# STM32F469 register map
File version: 1.9
CPU: CM4 r0p1, little endian, MPU, FPU, 4 interrupt priority bits
Registers are 32-bit, read-write, reset 0x0 unless marked. A register's access mark holds for its fields unless they carry their own. Offsets are from the block's base; [hi:lo] are bit positions; {n}, {i} and the like mark numbered series; <NAME> marks a mode.

## DSI — DSI Host
Base 0x40016C00
0x00 VR ro reset 0x3133302A — DSI Host version register
  [31:0] VERSION — Version of the DSI Host This read-only register contains the version of the DSI Host
0x04 CR — DSI Host control register
  [0] EN — Enable This bit configures the DSI Host in either power-up mode or to reset.
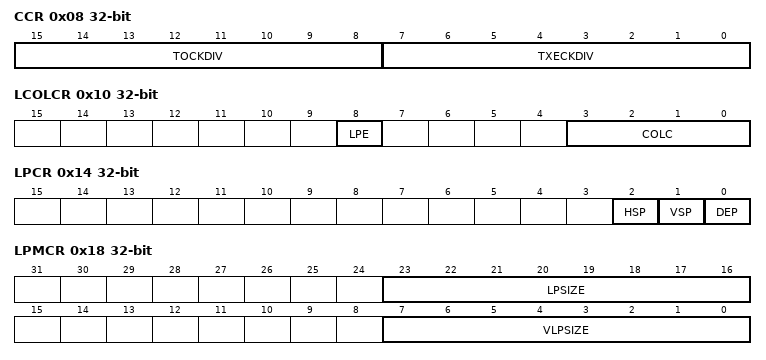
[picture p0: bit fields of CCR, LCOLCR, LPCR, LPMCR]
0x08 CCR — DSI Host clock control register
  [15:8] TOCKDIV — Timeout clock division This field indicates the division factor for the timeout clock used as the timing unit in the configuration of HS to LP and LP to HS transition error.
  [7:0] TXECKDIV — TX escape clock division This field indicates the division factor for the TX escape clock source (lanebyteclk). The values 0 and 1 stop the TX_ESC clock generation.
0x0C LVCIDR — DSI Host LTDC VCID register
  [1:0] VCID — Virtual channel ID These bits configure the virtual channel ID for the LTDC interface traffic.
0x10 LCOLCR — DSI Host LTDC color coding register
  [8] LPE — Loosely packet enable This bit enables the loosely packed variant to 18-bit configuration
  [3:0] COLC — Color coding This field configures the DPI color coding. Others: Reserved
0x14 LPCR — DSI Host LTDC polarity configuration register
  [2] HSP — HSYNC polarity This bit configures the polarity of HSYNC pin.
  [1] VSP — VSYNC polarity This bit configures the polarity of VSYNC pin.
  [0] DEP — Data enable polarity This bit configures the polarity of data enable pin.
0x18 LPMCR — DSI Host low-power mode configuration register
  [23:16] LPSIZE — Largest packet size This field is used for the transmission of commands in low-power mode. It defines the size, in bytes, of the largest packet that can fit in a line during VSA, VBP and VFP regions.
  [7:0] VLPSIZE — VACT largest packet size This field is used for the transmission of commands in low-power mode. It defines the size, in bytes, of the largest packet that can fit in a line during VACT regions.
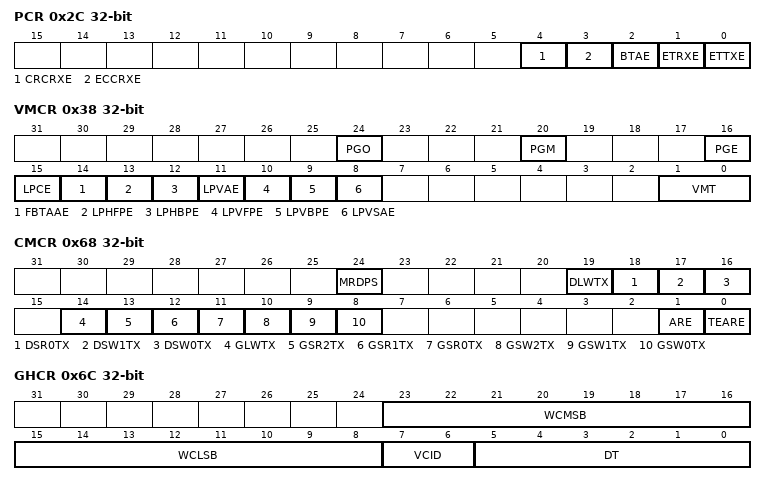
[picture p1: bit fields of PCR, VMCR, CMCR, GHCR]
0x2C PCR — DSI Host protocol configuration register
  [4] CRCRXE — CRC reception enable This bit enables the CRC reception and error reporting.
  [3] ECCRXE — ECC reception enable This bit enables the ECC reception, error correction and reporting.
  [2] BTAE — Bus-turn-around enable This bit enables the bus-turn-around (BTA) request.
  [1] ETRXE — EoTp reception enable This bit enables the EoTp reception.
  [0] ETTXE — EoTp transmission enable This bit enables the EoTP transmission.
0x30 GVCIDR — DSI Host generic VCID register
  [1:0] VCID — Virtual channel ID This field indicates the generic interface read-back virtual channel identification.
0x34 MCR reset 0x1 — DSI Host mode configuration register
  [0] CMDM — Command mode This bit configures the DSI Host in either video or command mode.
0x38 VMCR — DSI Host video mode configuration register
  [24] PGO — Pattern generator orientation This bit configures the color bar orientation.
  [20] PGM — Pattern generator mode This bit configures the pattern generator mode.
  [16] PGE — Pattern generator enable This bit enables the video mode pattern generator.
  [15] LPCE — Low-power command enable This bit enables the command transmission only in low-power mode.
  [14] FBTAAE — Frame bus-turn-around acknowledge enable This bit enables the request for an acknowledge response at the end of a frame.
  [13] LPHFPE — Low-power horizontal front-porch enable This bit enables the return to low-power inside the horizontal front-porch (HFP) period when timing allows.
  [12] LPHBPE — Low-power horizontal back-porch enable This bit enables the return to low-power inside the horizontal back-porch (HBP) period when timing allows.
  [11] LPVAE — Low-power vertical active enable This bit enables to return to low-power inside the vertical active (VACT) period when timing allows.
  [10] LPVFPE — Low-power vertical front-porch enable This bit enables to return to low-power inside the vertical front-porch (VFP) period when timing allows.
  [9] LPVBPE — Low-power vertical back-porch enable This bit enables to return to low-power inside the vertical back-porch (VBP) period when timing allows.
  [8] LPVSAE — Low-power vertical sync active enable This bit enables to return to low-power inside the vertical sync time (VSA) period when timing allows.
  [1:0] VMT — Video mode type This field configures the video mode transmission type : 1x: Burst mode
0x3C VPCR — DSI Host video packet configuration register
  [13:0] VPSIZE — Video packet size This field configures the number of pixels in a single video packet. For 18-bit not loosely packed data types, this number must be a multiple of 4. For YCbCr data types, it must be a multiple of 2 as described in the DSI specification.
0x40 VCCR — DSI Host video chunks configuration register
  [12:0] NUMC — Number of chunks This register configures the number of chunks to be transmitted during a line period (a chunk consists of a video packet and a null packet). If set to 0 or 1, the video line is transmitted in a single packet. If set to 1, the packet is part of a chunk, so a null packet follows it if NPSIZE > 0. Otherwise, multiple chunks are used to transmit each video line.
0x44 VNPCR — DSI Host video null packet configuration register
  [12:0] NPSIZE — Null packet size This field configures the number of bytes inside a null packet. Setting to 0 disables the null packets.
0x48 VHSACR — DSI Host video HSA configuration register
  [11:0] HSA — Horizontal synchronism active duration This fields configures the horizontal synchronism active period in lane byte clock cycles.
0x4C VHBPCR — DSI Host video HBP configuration register
  [11:0] HBP — Horizontal back-porch duration This fields configures the horizontal back-porch period in lane byte clock cycles.
0x50 VLCR — DSI Host video line configuration register
  [14:0] HLINE — Horizontal line duration This fields configures the total of the horizontal line period (HSA+HBP+HACT+HFP) counted in lane byte clock cycles.
0x54 VVSACR — DSI Host video VSA configuration register
  [9:0] VSA — Vertical synchronism active duration This fields configures the vertical synchronism active period measured in number of horizontal lines.
0x58 VVBPCR — DSI Host video VBP configuration register
  [9:0] VBP — Vertical back-porch duration This fields configures the vertical back-porch period measured in number of horizontal lines.
0x5C VVFPCR — DSI Host video VFP configuration register
  [9:0] VFP — Vertical front-porch duration This fields configures the vertical front-porch period measured in number of horizontal lines.
0x60 VVACR — DSI Host video VA configuration register
  [13:0] VA — Vertical active duration This fields configures the vertical active period measured in number of horizontal lines.
0x64 LCCR — DSI Host LTDC command configuration register
  [15:0] CMDSIZE — Command size This field configures the maximum allowed size for an LTDC write memory command, measured in pixels. Automatic partitioning of data obtained from LTDC is permanently enabled.
0x68 CMCR — DSI Host command mode configuration register
  [24] MRDPS — Maximum read packet size This bit configures the maximum read packet size command transmission type:
  [19] DLWTX — DCS long write transmission This bit configures the DCS long write packet command transmission type:
  [18] DSR0TX — DCS short read zero parameter transmission This bit configures the DCS short read packet with zero parameter command transmission type:
  [17] DSW1TX — DCS short read one parameter transmission This bit configures the DCS short read packet with one parameter command transmission type:
  [16] DSW0TX — DCS short write zero parameter transmission This bit configures the DCS short write packet with zero parameter command transmission type:
  [14] GLWTX — Generic long write transmission This bit configures the generic long write packet command transmission type :
  [13] GSR2TX — Generic short read two parameters transmission This bit configures the generic short read packet with two parameters command transmission type:
  [12] GSR1TX — Generic short read one parameters transmission This bit configures the generic short read packet with one parameters command transmission type:
  [11] GSR0TX — Generic short read zero parameters transmission This bit configures the generic short read packet with zero parameters command transmission type:
  [10] GSW2TX — Generic short write two parameters transmission This bit configures the generic short write packet with two parameters command transmission type:
  [9] GSW1TX — Generic short write one parameters transmission This bit configures the generic short write packet with one parameters command transmission type:
  [8] GSW0TX — Generic short write zero parameters transmission This bit configures the generic short write packet with zero parameters command transmission type:
  [1] ARE — Acknowledge request enable This bit enables the acknowledge request after each packet transmission:
  [0] TEARE — Tearing effect acknowledge request enable This bit enables the tearing effect acknowledge request:
0x6C GHCR — DSI Host generic header configuration register
  [23:16] WCMSB — WordCount MSB This field configures the most significant byte of the header packet word count for long packets, or data 1 for short packets.
  [15:8] WCLSB — WordCount LSB This field configures the less significant byte of the header packet word count for long packets, or data 0 for short packets.
  [7:6] VCID — Channel This field configures the virtual channel ID of the header packet.
  [5:0] DT — Type This field configures the packet data type of the header packet.
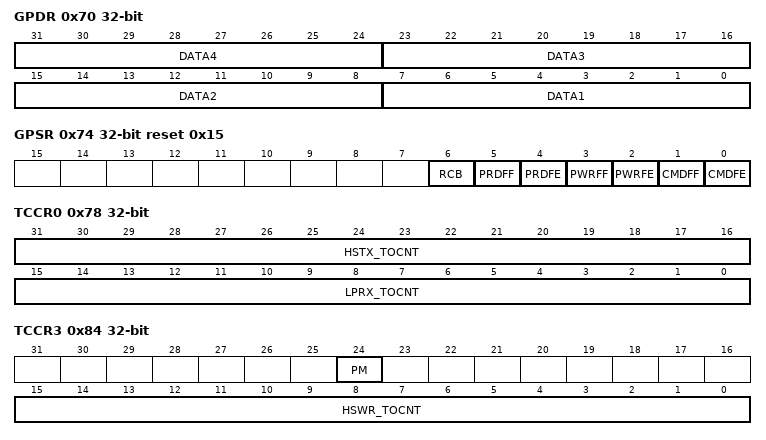
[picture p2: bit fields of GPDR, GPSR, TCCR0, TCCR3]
0x70 GPDR — DSI Host generic payload data register
  [8n-1:8n-8] DATA{n} (n=1..4) — Payload byte {n} This field indicates the byte {n} of the packet payload.
0x74 GPSR ro reset 0x15 — DSI Host generic packet status register
  [6] RCB — Read command busy This bit is set when a read command is issued and cleared when the entire response is stored in the FIFO:
  [5] PRDFF — Payload read FIFO full This bit indicates the full status of the generic read payload FIFO:
  [4] PRDFE — Payload read FIFO empty This bit indicates the empty status of the generic read payload FIFO:
  [3] PWRFF — Payload write FIFO full This bit indicates the full status of the generic write payload FIFO:
  [2] PWRFE — Payload write FIFO empty This bit indicates the empty status of the generic write payload FIFO:
  [1] CMDFF — Command FIFO full This bit indicates the full status of the generic command FIFO:
  [0] CMDFE — Command FIFO empty This bit indicates the empty status of the generic command FIFO:
0x78 TCCR0 — DSI Host timeout counter configuration register 0
  [31:16] HSTX_TOCNT — High-speed transmission timeout counter This field configures the timeout counter that triggers a high-speed transmission timeout contention detection (measured in TOCKDIV cycles).
  [15:0] LPRX_TOCNT — Low-power reception timeout counter This field configures the timeout counter that triggers a low-power reception timeout contention detection (measured in TOCKDIV cycles).
0x7C TCCR1 — DSI Host timeout counter configuration register 1
  [15:0] HSRD_TOCNT — High-speed read timeout counter This field sets a period for which the DSI Host keeps the link still, after sending a high-speed read operation. This period is measured in cycles of lanebyteclk. The counting starts when the D-PHY enters the Stop state and causes no interrupts.
0x80 TCCR2 — DSI Host timeout counter configuration register 2
  [15:0] LPRD_TOCNT — Low-power read timeout counter This field sets a period for which the DSI Host keeps the link still, after sending a low-power read operation. This period is measured in cycles of lanebyteclk. The counting starts when the D-PHY enters the Stop state and causes no interrupts.
0x84 TCCR3 — DSI Host timeout counter configuration register 3
  [24] PM — Presp mode When set to 1, this bit ensures that the peripheral response timeout caused by HSWR_TOCNT is used only once per LTDC frame in command mode, when both the following conditions are met: dpivsync_edpiwms has risen and fallen. Packets originated from LTDC in command mode have been transmitted and its FIFO is empty again. In this scenario no non-LTDC command requests are sent to the D-PHY, even if there is traffic from generic interface ready to be sent, making it return to stop state. When it does so, PRESP_TO counter is activated and only when it finishes does the controller send any other traffic that is ready.
  [15:0] HSWR_TOCNT — High-speed write timeout counter This field sets a period for which the DSI Host keeps the link inactive after sending a high-speed write operation. This period is measured in cycles of lanebyteclk. The counting starts when the D-PHY enters the Stop state and causes no interrupts.
0x88 TCCR4 — DSI Host timeout counter configuration register 4
  [15:0] LPWR_TOCNT — Low-power write timeout counter This field sets a period for which the DSI Host keeps the link still, after sending a low-power write operation. This period is measured in cycles of lanebyteclk. The counting starts when the D-PHY enters the Stop state and causes no interrupts.
0x8C TCCR5 — DSI Host timeout counter configuration register 5
  [15:0] BTA_TOCNT — Bus-turn-around timeout counter This field sets a period for which the DSI Host keeps the link still, after completing a bus-turn-around. This period is measured in cycles of lanebyteclk. The counting starts when the D-PHY enters the Stop state and causes no interrupts.
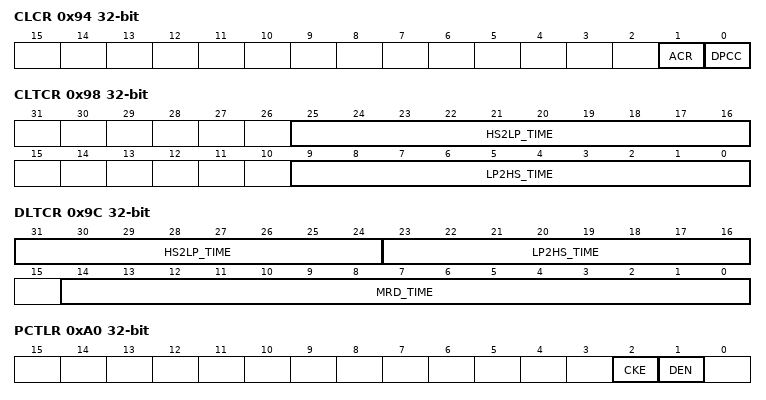
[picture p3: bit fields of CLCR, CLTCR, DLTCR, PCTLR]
0x94 CLCR — DSI Host clock lane configuration register
  [1] ACR — Automatic clock lane control This bit enables the automatic mechanism to stop providing clock in the clock lane when time allows.
  [0] DPCC — D-PHY clock control This bit controls the D-PHY clock state:
0x98 CLTCR — DSI Host clock lane timer configuration register
  [25:16] HS2LP_TIME — High-speed to low-power time This field configures the maximum time that the D-PHY clock lane takes to go from high speed to low-power transmission measured in lane byte clock cycles.
  [9:0] LP2HS_TIME — Low-power to high-speed time This field configures the maximum time that the D-PHY clock lane takes to go from low power to high-speed transmission measured in lane byte clock cycles.
0x9C DLTCR — DSI Host data lane timer configuration register
  [31:24] HS2LP_TIME — High-speed to low-power time This field configures the maximum time that the D-PHY data lanes take to go from high-speed to low-power transmission measured in lane byte clock cycles.
  [23:16] LP2HS_TIME — Low-power to high-speed time This field configures the maximum time that the D-PHY data lanes take to go from low-power to high-speed transmission measured in lane byte clock cycles.
  [14:0] MRD_TIME — Maximum read time This field configures the maximum time required to perform a read command in lane byte clock cycles. This register can only be modified when no read command is in progress.
0xA0 PCTLR — DSI Host PHY control register
  [2] CKE — Clock enable This bit enables the D-PHY clock lane module:
  [1] DEN — Digital enable When set to 0, this bit places the digital section of the D-PHY in the reset state
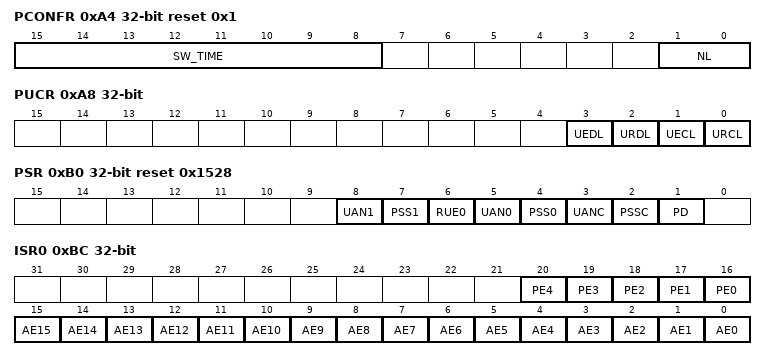
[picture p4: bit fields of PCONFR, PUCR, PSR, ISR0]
0xA4 PCONFR reset 0x1 — DSI Host PHY configuration register
  [15:8] SW_TIME — Stop wait time This field configures the minimum wait period to request a high-speed transmission after the Stop state.
  [1:0] NL — Number of lanes This field configures the number of active data lanes: Others: Reserved
0xA8 PUCR — DSI Host PHY ULPS control register
  [3] UEDL — ULPS exit on data lane ULPS mode exit on all active data lanes.
  [2] URDL — ULPS request on data lane ULPS mode request on all active data lanes.
  [1] UECL — ULPS exit on clock lane ULPS mode exit on clock lane.
  [0] URCL — ULPS request on clock lane ULPS mode request on clock lane.
0xAC PTTCR — DSI Host PHY TX triggers configuration register
  [3:0] TX_TRIG — Transmission trigger Escape mode transmit trigger 0-3. Only one bit of TX_TRIG is asserted at any given time.
0xB0 PSR ro reset 0x1528 — DSI Host PHY status register
  [8] UAN1 — ULPS active not lane 1 This bit indicates the status of ulpsactivenot1lane D-PHY signal.
  [7] PSS1 — PHY stop state lane 1 This bit indicates the status of phystopstate1lane D-PHY signal.
  [6] RUE0 — RX ULPS escape lane 0 This bit indicates the status of rxulpsesc0lane D-PHY signal.
  [5] UAN0 — ULPS active not lane 1 This bit indicates the status of ulpsactivenot0lane D-PHY signal.
  [4] PSS0 — PHY stop state lane 0 This bit indicates the status of phystopstate0lane D-PHY signal.
  [3] UANC — ULPS active not clock lane This bit indicates the status of ulpsactivenotclklane D-PHY signal.
  [2] PSSC — PHY stop state clock lane This bit indicates the status of phystopstateclklane D-PHY signal.
  [1] PD — PHY direction This bit indicates the status of phydirection D-PHY signal.
0xBC ISR0 ro — DSI Host interrupt and status register 0
  [n+16] PE{n} (n=0..4) — PHY error {n}
  [n] AE{n} (n=0..15) — Acknowledge error {n}
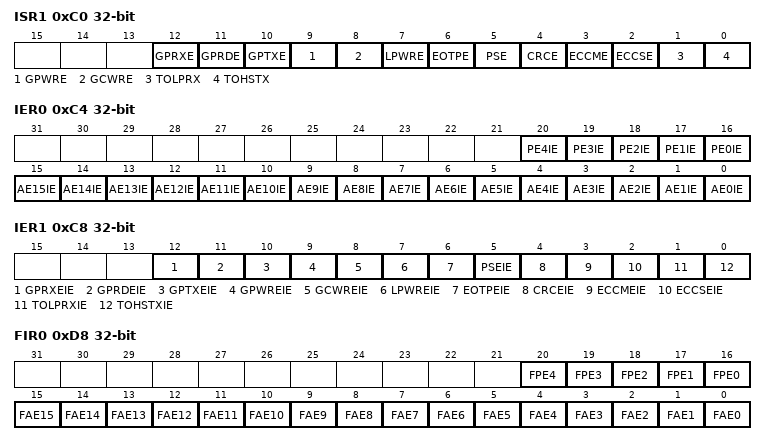
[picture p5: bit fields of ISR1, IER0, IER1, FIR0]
0xC0 ISR1 ro — DSI Host interrupt and status register 1
  [12] GPRXE — Generic payload receive error This bit indicates that during a generic interface packet read back, the payload FIFO becomes full and the received data is corrupted.
  [11] GPRDE — Generic payload read error This bit indicates that during a DCS read data, the payload FIFO becomes empty and the data sent to the interface is corrupted.
  [10] GPTXE — Generic payload transmit error This bit indicates that during a generic interface packet build, the payload FIFO becomes empty and corrupt data is sent.
  [9] GPWRE — Generic payload write error This bit indicates that the system tried to write a payload data through the generic interface and the FIFO is full. Therefore, the payload is not written.
  [8] GCWRE — Generic command write error This bit indicates that the system tried to write a command through the generic interface and the FIFO is full. Therefore, the command is not written.
  [7] LPWRE — LTDC payload write error This bit indicates that during a DPI pixel line storage, the payload FIFO becomes full and the data stored is corrupted.
  [6] EOTPE — EoTp error This bit indicates that the EoTp packet is not received at the end of the incoming peripheral transmission.
  [5] PSE — Packet size error This bit indicates that the packet size error is detected during the packet reception.
  [4] CRCE — CRC error This bit indicates that the CRC error is detected in the received packet payload.
  [3] ECCME — ECC multi-bit error This bit indicates that the ECC multiple error is detected in a received packet.
  [2] ECCSE — ECC single-bit error This bit indicates that the ECC single error is detected and corrected in a received packet.
  [1] TOLPRX — Timeout low-power reception This bit indicates that the low-power reception timeout counter reached the end and contention is detected.
  [0] TOHSTX — Timeout high-speed transmission This bit indicates that the high-speed transmission timeout counter reached the end and contention is detected.
0xC4 IER0 — DSI Host interrupt enable register 0
  [n+16] PE{n}IE (n=0..4) — PHY error {n} interrupt enable
  [n] AE{n}IE (n=0..15) — Acknowledge error {n} interrupt enable
0xC8 IER1 — DSI Host interrupt enable register 1
  [12] GPRXEIE — Generic payload receive error interrupt enable This bit enables the interrupt generation on generic payload receive error.
  [11] GPRDEIE — Generic payload read error interrupt enable This bit enables the interrupt generation on generic payload read error.
  [10] GPTXEIE — Generic payload transmit error interrupt enable This bit enables the interrupt generation on generic payload transmit error.
  [9] GPWREIE — Generic payload write error interrupt enable This bit enables the interrupt generation on generic payload write error.
  [8] GCWREIE — Generic command write error interrupt enable This bit enables the interrupt generation on generic command write error.
  [7] LPWREIE — LTDC payload write error interrupt enable This bit enables the interrupt generation on LTDC payload write error.
  [6] EOTPEIE — EoTp error interrupt enable This bit enables the interrupt generation on EoTp error.
  [5] PSEIE — Packet size error interrupt enable This bit enables the interrupt generation on packet size error.
  [4] CRCEIE — CRC error interrupt enable This bit enables the interrupt generation on CRC error.
  [3] ECCMEIE — ECC multi-bit error interrupt enable This bit enables the interrupt generation on ECC multi-bit error.
  [2] ECCSEIE — ECC single-bit error interrupt enable This bit enables the interrupt generation on ECC single-bit error.
  [1] TOLPRXIE — Timeout low-power reception interrupt enable This bit enables the interrupt generation on timeout low-power reception.
  [0] TOHSTXIE — Timeout high-speed transmission interrupt enable This bit enables the interrupt generation on timeout high-speed transmission .
0xD8 FIR0 wo — DSI Host force interrupt register 0
  [n+16] FPE{n} (n=0..4) — Force PHY error {n}
  [n] FAE{n} (n=0..15) — Force acknowledge error {n}
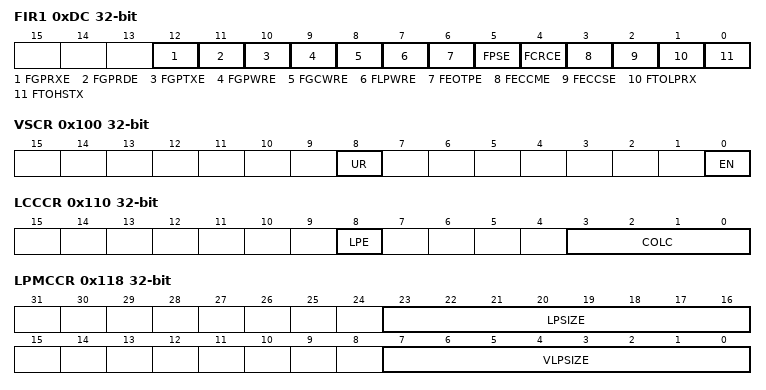
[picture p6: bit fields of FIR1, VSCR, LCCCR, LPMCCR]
0xDC FIR1 wo — DSI Host force interrupt register 1
  [12] FGPRXE — Force generic payload receive error Writing one to this bit forces a generic payload receive error.
  [11] FGPRDE — Force generic payload read error Writing one to this bit forces a generic payload read error.
  [10] FGPTXE — Force generic payload transmit error Writing one to this bit forces a generic payload transmit error.
  [9] FGPWRE — Force generic payload write error Writing one to this bit forces a generic payload write error.
  [8] FGCWRE — Force generic command write error Writing one to this bit forces a generic command write error.
  [7] FLPWRE — Force LTDC payload write error Writing one to this bit forces a LTDC payload write error.
  [6] FEOTPE — Force EoTp error Writing one to this bit forces a EoTp error.
  [5] FPSE — Force packet size error Writing one to this bit forces a packet size error.
  [4] FCRCE — Force CRC error Writing one to this bit forces a CRC error.
  [3] FECCME — Force ECC multi-bit error Writing one to this bit forces a ECC multi-bit error.
  [2] FECCSE — Force ECC single-bit error Writing one to this bit forces a ECC single-bit error.
  [1] FTOLPRX — Force timeout low-power reception Writing one to this bit forces a timeout low-power reception.
  [0] FTOHSTX — Force timeout high-speed transmission Writing one to this bit forces a timeout high-speed transmission.
0x100 VSCR — DSI Host video shadow control register
  [8] UR — Update register When set to 1, the LTDC registers are copied to the auxiliary registers. After copying, this bit is auto cleared.
  [0] EN — Enable When set to 1, DSI Host LTDC interface receives the active configuration from the auxiliary registers. When this bit is set along with the UR bit, the auxiliary registers are automatically updated.
0x10C LCVCIDR — DSI Host LTDC current VCID register
  [1:0] VCID — Virtual channel ID This field returns the virtual channel ID for the LTDC interface.
0x110 LCCCR ro — DSI Host LTDC current color coding register
  [8] LPE — Loosely packed enable This bit returns the current state of the loosely packed variant to 18-bit configurations.
  [3:0] COLC — Color coding This field returns the current LTDC interface color coding. If LTDC interface in command mode is chosen and currently works in the command mode (CMDM=1), then 0110-1111: 24-bit
0x118 LPMCCR ro — DSI Host low-power mode current configuration register
  [23:16] LPSIZE — Largest packet size This field is returns the current size, in bytes, of the largest packet that can fit in a line during VSA, VBP and VFP regions, for the transmission of commands in low-power mode.
  [7:0] VLPSIZE — VACT largest packet size This field returns the current size, in bytes, of the largest packet that can fit in a line during VACT regions, for the transmission of commands in low-power mode.
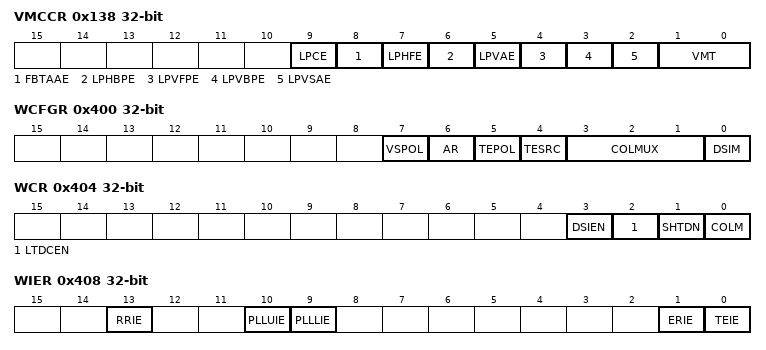
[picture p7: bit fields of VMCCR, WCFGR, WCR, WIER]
0x138 VMCCR ro — DSI Host video mode current configuration register
  [9] LPCE — Low-power command enable This bit returns the current command transmission state in low-power mode.
  [8] FBTAAE — Frame BTA acknowledge enable This bit returns the current state of request for an acknowledge response at the end of a frame.
  [7] LPHFE — Low-power horizontal front-porch enable This bit returns the current state of return to low-power inside the horizontal front-porch (HFP) period when timing allows.
  [6] LPHBPE — Low-power horizontal back-porch enable This bit returns the current state of return to low-power inside the horizontal back-porch (HBP) period when timing allows.
  [5] LPVAE — Low-power vertical active enable This bit returns the current state of return to low-power inside the vertical active (VACT) period when timing allows.
  [4] LPVFPE — Low-power vertical front-porch enable This bit returns the current state of return to low-power inside the vertical front-porch (VFP) period when timing allows.
  [3] LPVBPE — Low-power vertical back-porch enable This bit returns the current state of return to low-power inside the vertical back-porch (VBP) period when timing allows.
  [2] LPVSAE — Low-power vertical sync time enable This bit returns the current state of return to low-power inside the vertical sync time (VSA) period when timing allows.
  [1:0] VMT — Video mode type This field returns the current video mode transmission type: 1x: Burst mode
0x13C VPCCR ro — DSI Host video packet current configuration register
  [13:0] VPSIZE — Video packet size This field returns the number of pixels in a single video packet.
0x140 VCCCR ro — DSI Host video chunks current configuration register
  [12:0] NUMC — Number of chunks This field returns the number of chunks being transmitted during a line period.
0x144 VNPCCR ro — DSI Host video null packet current configuration register
  [12:0] NPSIZE — Null packet size This field returns the number of bytes inside a null packet.
0x148 VHSACCR ro — DSI Host video HSA current configuration register
  [11:0] HSA — Horizontal synchronism active duration This fields returns the horizontal synchronism active period in lane byte clock cycles.
0x14C VHBPCCR ro — DSI Host video HBP current configuration register
  [11:0] HBP — Horizontal back-porch duration This field returns the horizontal back-porch period in lane byte clock cycles.
0x150 VLCCR ro — DSI Host video line current configuration register
  [14:0] HLINE — Horizontal line duration This field returns the current total of the horizontal line period (HSA+HBP+HACT+HFP) counted in lane byte clock cycles.
0x154 VVSACCR ro — DSI Host video VSA current configuration register
  [9:0] VSA — Vertical synchronism active duration This field returns the current vertical synchronism active period measured in number of horizontal lines.
0x158 VVBPCCR ro — DSI Host video VBP current configuration register
  [9:0] VBP — Vertical back-porch duration This field returns the current vertical back-porch period measured in number of horizontal lines.
0x15C VVFPCCR ro — DSI Host video VFP current configuration register
  [9:0] VFP — Vertical front-porch duration This field returns the current vertical front-porch period measured in number of horizontal lines.
0x160 VVACCR ro — DSI Host video VA current configuration register
  [13:0] VA — Vertical active duration This field returns the current vertical active period measured in number of horizontal lines.
0x400 WCFGR — DSI Wrapper configuration register
  [7] VSPOL — VSync polarity This bit selects the VSync edge on which the LTDC is halted. This bit must only be changed when DSI is stopped (DSI_WCR.DSIEN = 0 and DSI_CR.EN=0).
  [6] AR — Automatic refresh This bit selects the refresh mode in DBI mode. This bit must only be changed when DSI Host is stopped (DSI_CR.EN = 0).
  [5] TEPOL — TE polarity This bit selects the polarity of the external pin tearing effect (TE) source. This bit must only be changed when DSI Host is stopped (DSI_CR.EN = 0).
  [4] TESRC — TE source This bit selects the tearing effect (TE) source. This bit must only be changed when DSI Host is stopped (DSI_CR.EN = 0).
  [3:1] COLMUX — Color multiplexing This bit selects the color multiplexing used by DSI Host. This field must only be changed when DSI is stopped (DSI_WCR.DSIEN = 0 and DSI_CR.EN=0).
  [0] DSIM — DSI mode This bit selects the mode for the video transmission. This bit must only be changed when DSI Host is stopped (DSI_CR.EN = 0).
0x404 WCR — DSI Wrapper control register
  [3] DSIEN — DSI enable This bit enables the DSI Wrapper.
  [2] LTDCEN — LTDC enable This bit enables the LTDC for a frame transfer in adapted command mode.
  [1] SHTDN — Shutdown This bit controls the display shutdown in video mode.
  [0] COLM — Color mode This bit controls the display color mode in video mode.
0x408 WIER — DSI Wrapper interrupt enable register
  [13] RRIE — Regulator ready interrupt enable This bit enables the regulator ready interrupt.
  [10] PLLUIE — PLL unlock interrupt enable This bit enables the PLL unlock interrupt.
  [9] PLLLIE — PLL lock interrupt enable This bit enables the PLL lock interrupt.
  [1] ERIE — End of refresh interrupt enable This bit enables the end of refresh interrupt.
  [0] TEIE — Tearing effect interrupt enable This bit enables the tearing effect interrupt.
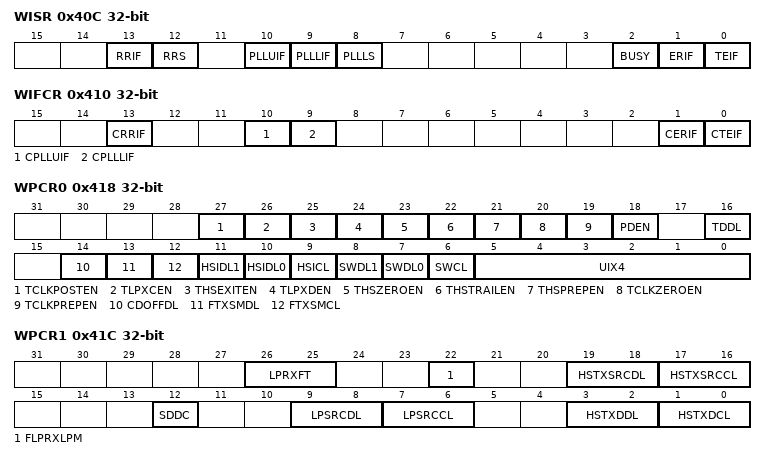
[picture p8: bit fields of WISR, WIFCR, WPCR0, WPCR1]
0x40C WISR ro — DSI Wrapper interrupt and status register
  [13] RRIF — Regulator ready interrupt flag This bit is set when the regulator becomes ready.
  [12] RRS — Regulator ready status This bit gives the status of the regulator.
  [10] PLLUIF — PLL unlock interrupt flag This bit is set when the PLL becomes unlocked.
  [9] PLLLIF — PLL lock interrupt flag This bit is set when the PLL becomes locked.
  [8] PLLLS — PLL lock status This bit is set when the PLL is locked and cleared when it is unlocked.
  [2] BUSY — Busy flag This bit is set when the transfer of a frame in adapted command mode is ongoing.
  [1] ERIF — End of refresh interrupt flag This bit is set when the transfer of a frame in adapted command mode is finished.
  [0] TEIF — Tearing effect interrupt flag This bit is set when a tearing effect event occurs.
0x410 WIFCR wo — DSI Wrapper interrupt flag clear register
  [13] CRRIF — Clear regulator ready interrupt flag Write 1 clears the RRIF flag in the DSI_WSR register.
  [10] CPLLUIF — Clear PLL unlock interrupt flag Write 1 clears the PLLUIF flag in the DSI_WSR register.
  [9] CPLLLIF — Clear PLL lock interrupt flag Write 1 clears the PLLLIF flag in the DSI_WSR register.
  [1] CERIF — Clear end of refresh interrupt flag Write 1 clears the ERIF flag in the DSI_WSR register.
  [0] CTEIF — Clear tearing effect interrupt flag Write 1 clears the TEIF flag in the DSI_WSR register.
0x418 WPCR0 — DSI Wrapper PHY configuration register 0
  [27] TCLKPOSTEN — Custom time for t<sub>CLK-POST</sub> enable This bit enables the manual programming of t<sub>CLK-POST </sub>duration in the D-PHY. The desired value must be programmed in the TCLKPOST field of the DSI_WPCR4 register.
  [26] TLPXCEN — Custom time for t<sub>LPX</sub> for clock lane enable This bit enables the manual programming of t<sub>LPX</sub> duration for the clock lane in the D-PHY. The desired value must be programmed in the TLPXC field of the DSI_WPCR3 register.
  [25] THSEXITEN — Custom time for t<sub>HS-EXIT</sub> enable This bit enables the manual programming of t<sub>HS-EXIT </sub>duration in the D-PHY. The desired value must be programmed in the THSEXIT field of the DSI_WPCR3 register.
  [24] TLPXDEN — Custom time for t<sub>LPX</sub> for data lanes enable This bit enables the manual programming of T<sub>LPX </sub>duration for the data lanes in the D-PHY. The desired value must be programmed in the TLPXD field of the DSI_WPCR3 register.
  [23] THSZEROEN — Custom time for t<sub>HS-ZERO</sub> enable This bit enables the manual programming of t<sub>HS-ZERO </sub>duration in the D-PHY. The desired value must be programmed in the THSZERO field of the DSI_WPCR3 register.
  [22] THSTRAILEN — Custom time for t<sub>HS-TRAIL</sub> enable This bit enables the manual programming of T<sub>HS-TRAIL </sub>duration in the D-PHY. The desired value must be programmed in the THSRAIL field of the DSI_WPCR2 register.
  [21] THSPREPEN — Custom time for t<sub>HS-PREPARE</sub> enable This bit enables the manual programming of t<sub>HS-PREPARE </sub>duration in the D-PHY. The desired value must be programmed in the THSPREP field of the DSI_WPCR2 register.
  [20] TCLKZEROEN — Custom time for t<sub>CLK-ZERO</sub> enable This bit enables the manual programming of t<sub>CLK-ZERO </sub>duration in the D-PHY. The desired value must be programmed in the TCLKZERO field of the DSI_WPCR2 register.
  [19] TCLKPREPEN — Custom time for t<sub>CLK-PREPARE</sub> enable This bit enables the manual programming of t<sub>CLK-PREPARE </sub>duration in the D-PHY. The desired value must be programmed in the TLKCPREP field of the DSI_WPCR2 register.
  [18] PDEN — Pull-down enable This bit enables a pull-down on the lane to prevent from floating states when unused.
  [16] TDDL — Turn disable data lanes This bit forces the data lane to remain in RX event if it receives a bus-turn-around request from the other side.
  [14] CDOFFDL — Contention detection OFF on data lanes When only forward escape mode is used, this signal can be made high to switch off the contention detector and reduce static power consumption.
  [13] FTXSMDL — Force in TX Stop mode the data lanes This bit forces the data lanes in TX stop mode. It is used to initialize a lane module in transmit mode. It causes the lane module to immediately jump to transmit control mode and to begin transmitting a stop state (LP-11). It can be used to go back in TX mode after a wrong BTA sequence.
  [12] FTXSMCL — Force in TX Stop mode the clock lane This bit forces the clock lane in TX stop mode. It is used to initialize a lane module in transmit mode. It causes the lane module to immediately jump to transmit control mode and to begin transmitting a stop state (LP-11). It can be used to go back in TX mode after a wrong BTA sequence.
  [11] HSIDL1 — Invert the high-speed data signal on data lane 1 This bit inverts the high-speed data signal on data lane 1.
  [10] HSIDL0 — Invert the high-speed data signal on data lane 0 This bit inverts the high-speed data signal on clock lane.
  [9] HSICL — Invert high-speed data signal on clock lane This bit inverts the high-speed data signal on clock lane.
  [8] SWDL1 — Swap data lane 1 pins This bit swaps the pins on clock lane.
  [7] SWDL0 — Swap data lane 0 pins This bit swaps the pins on data lane 0.
  [6] SWCL — Swap clock lane pins This bit swaps the pins on clock lane.
  [5:0] UIX4 — Unit interval multiplied by 4 This field defines the bit period in high-speed mode in unit of 0.25 ns. As an example, if the unit interval is 3 ns, a value of twelve (0x0C) must be driven to this input. This value is used to generate delays. If the period is not a multiple of 0.25 ns, the value driven must be rounded down. For example, a 600 Mbit/s link uses a unit interval of 1.667 ns, which, multiplied by four gives 6.667 ns. In this case a value of 6 (not 7) must be driven onto the ui_x4 input.
0x41C WPCR1 — DSI Wrapper PHY configuration register 1
  [26:25] LPRXFT — Low-power RX low-pass filtering tuning This signal can be used to tune the cutoff frequency of low-pass filter at the input of LPRX.
  [22] FLPRXLPM — Forces LP receiver in low-power mode This bit enables the low-power mode of LP receiver (LPRX). When set, the LPRX operates in low-power mode all the time (when this is not activated, LPRX operates in low power mode during ULPS only).
  [19:18] HSTXSRCDL — High-speed transmission slew-rate control on data lanes Slew-rate control for high-speed transmitter output. It can be used to change slew-rate of data lane HS transitions. Default value = 00.
  [17:16] HSTXSRCCL — High-speed transmission slew-rate control on clock lane Slew-rate control for high-speed transmitter output. It can be used to change slew-rate of clock lane HS transitions. Default value = 00.
  [12] SDDC — SDD control This bit switches on the additional current path to meet the SDDTx parameter defined by MIPI<sup></sup> D-PHY Specification on both clock and data lanes.
  [9:8] LPSRCDL — Low-power transmission slew-rate compensation on data lanes Can be used to change slew-rate of data lane LP transitions. Default value = 00.
  [7:6] LPSRCCL — Low-power transmission slew-rate compensation on clock lane Can be used to change slew-rate of clock lane LP transitions. Default value = 00.
  [3:2] HSTXDDL — High-speed transmission delay on data lanes Delay tuner control to change delay (up to DP/DN) in data path. Can be used to change data edge transition positions with respect to clock edge on DP/DN. Default value = 00.
  [1:0] HSTXDCL — High-speed transmission delay on clock lane Delay tuner control to change delay (up to DP/DN) in clock path. Can be used to change clock edge position with respect to data bit transitions on DP/DN. Default value = 00.
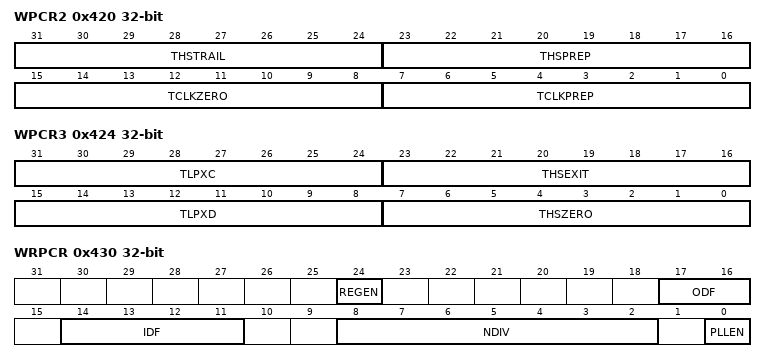
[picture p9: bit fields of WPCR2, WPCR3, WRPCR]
0x420 WPCR2 — DSI Wrapper PHY configuration register 2
  [31:24] THSTRAIL — t<sub>HSTRAIL</sub> This field defines the t<sub>HS-TRAIL</sub> has specified in the MIPI<sup></sup> D-PHY specification. This value is used by the D-PHY when the THSTRAILEN bit of the DSI_WPCR0 is set. THSTRAIL = 2 x t<sub>HS-TRAIL</sub> expressed in ns.The default value used by the D-PHY when THSTRAILEN bit of the DSI_WPCR0 is reset is 140 (70ns+8*UI).
  [23:16] THSPREP — t<sub>HS-PREPARE</sub> This field defines the t<sub>HS-PREPARE</sub> has specified in the MIPI<sup></sup> D-PHY specification. This value is used by the D-PHY when the THSPREPEN bit of the DSI_WPCR0 is set. THSPREP = 2 x t<sub>HS-PREPARE</sub> expressed in ns.The default value used by the D-PHY when THSPREPEN bit of the DSI_WPCR0 is reset is 126 (63ns + 12*UI).
  [15:8] TCLKZERO — t<sub>CLK-ZERO</sub> This field defines the t<sub>CLK-ZERO</sub> has specified in the MIPI<sup></sup> D-PHY specification. This value is used by the D-PHY when the TCLKZEROEN bit of the DSI_WPCR0 is set. TCLKZERO = t<sub>CLK-ZERO</sub> / 2 expressed in ns.The default value used by the D-PHY when TCLKZEROEN bit of the DSI_WPCR0 is reset is 195 (390ns).
  [7:0] TCLKPREP — t<sub>CLK-PREPARE</sub> This field defines the t<sub>CLK-PREPARE</sub> has specified in the MIPI<sup></sup> D-PHY specification. This value is used by the D-PHY when the TCLKPREPEN bit of the DSI_WPCR0 is set. TCLKPREP = 2 x t<sub>CLK-PREPARE</sub> expressed in ns.The default value used by the D-PHY when TCLKPREPEN bit of the DSI_WPCR0 is reset is 120 (60ns + 20*UI).
0x424 WPCR3 — DSI Wrapper PHY configuration register 3
  [31:24] TLPXC — t<sub>LPXC</sub> for clock lane This field defines the t<sub>LPX</sub> has specified in the MIPI<sup></sup> D-PHY specification for the clock lane. This value is used by the D-PHY when the TLPXCEN bit of the DSI_WPCR1 is set. TLPXC = 2 x t<sub>LPX</sub> expressed in ns.The default value used by the D-PHY when TLPXCEN bit of the DSI_WPCR1 is reset is 100 (50ns).
  [23:16] THSEXIT — t<sub>HSEXIT</sub> This field defines the t<sub>HS-EXHigh-SpeedIT</sub> has specified in the MIPI<sup></sup> D-PHY specification. This value is used by the D-PHY when the THSEXITEN bit of the DSI_WPCR1 is set. THSEXIT = t<sub>HS-ZERO</sub> expressed in ns.The default value used by the D-PHY when THSEXITEN bit of the DSI_WPCR1 is reset is 100 (100ns).
  [15:8] TLPXD — t<sub>LPX</sub> for data lanes This field defines the t<sub>LPX</sub> has specified in the MIPI<sup></sup> D-PHY specification for the data lanes. This value is used by the D-PHY when the TLPXDEN bit of the DSI_WPCR1 is set. TLPXD = 2 x t<sub>LPX</sub> expressed in ns.The default value used by the D-PHY when TLPXDEN bit of the DSI_WPCR1 is reset is 100 (50ns).
  [7:0] THSZERO — t<sub>HS-ZERO</sub> This field defines the t<sub>HS-ZERO</sub> has specified in the MIPI<sup></sup> D-PHY specification. This value is used by the D-PHY when the THSZEROEN bit of the DSI_WPCR1 is set. THSZERO = t<sub>HS-ZERO</sub> expressed in ns.The default value used by the D-PHY when THSZEROEN bit of the DSI_WPCR1 is reset is 175, (175ns).
0x428 WPCR4 — DSI Wrapper PHY configuration register 4
  [7:0] TCLKPOST — t<sub>CLK-POST</sub> This field defines the t<sub>CLK-POST</sub> has specified in the MIPI<sup></sup> D-PHY specification. This value is used by the D-PHY when the TCLKPOSTEN bit of the DSI_WPCR0 is set. TCLKPOST = 2 x t<sub>CLK-POST</sub> expressed in ns.The default value used by the D-PHY when TCLKPOSTEN bit of the DSI_WPCR0 is reset is 200 (100ns + 120*UI).
0x430 WRPCR — DSI Wrapper regulator and PLL control register
  [24] REGEN — Regulator enable This bit enables the DPHY regulator.
  [17:16] ODF — PLL output division factor This field configures the PLL output division factor.
  [14:11] IDF — PLL input division factor This field configures the PLL input division factor.
  [8:2] NDIV — PLL loop division factor This field configures the PLL loop division factor. 10 to 125: Allowed loop division factor values Others: Reserved
  [0] PLLEN — PLL enable This bit enables the D-PHY PLL.
